# V3s register map
Vendor: Allwinner; Series: V3s; File version: 0.1
CPU: ARM Cortex-A7 MP1 0, little endian, MPU, no FPU, 0 interrupt priority bits
Registers are 32-bit, read-write, reset 0x0 unless marked. A register's access mark holds for its fields unless they carry their own. Offsets are from the block's base; [hi:lo] are bit positions; {n}, {i} and the like mark numbered series; 'fields as' and 'values as' point back to an identical list.

## CSI0
Base 0x01CB0000
Same registers: CSI1 0x01CB4000
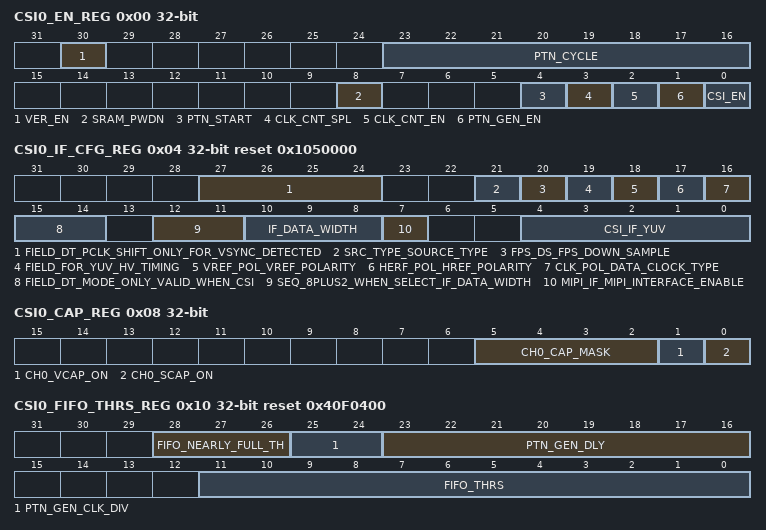
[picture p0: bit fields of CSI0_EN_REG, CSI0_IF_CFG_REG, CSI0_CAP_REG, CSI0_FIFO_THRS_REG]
0x00 CSI0_EN_REG
  [30] VER_EN — CSI Version Register Read Enable: 0: Disable 1: Enable
    0=Disable; 1=Enable
  [23:16] PTN_CYCLE — Pattern generating cycle counter. The pattern in dram will be generated in cycles of PTN_CYCLE+1.
  [8] SRAM_PWDN — 0: SRAM in normal 1: SRAM in power down
    0=SRAM_in_normal; 1=SRAM in power down
  [4] PTN_START — CSI Pattern Generating Start 0: Finish other: Start Software write this bit to 1 to start pattern generating from DRAM. When finished, the hardware will clear this bit to 0 automatically. Generating cycles depends on PTN_CYCLE.
    0=Finish other: Start Software write this bit to 1 to start pattern generating from DRAM. When finished, the hardware will clear this bit to 0 automatically. Generating cycles depends on PTN_CYCLE.
  [3] CLK_CNT_SPL — Sampling time for clk counter per frame 0: Sampling clock counter every frame done 1: Sampling clock counter every vsync
    0=Sampling clock counter every frame done; 1=Sampling_clock_counter_every_vsync
  [2] CLK_CNT_EN — clk count per frame enable
  [1] PTN_GEN_EN — Pattern Generation Enable
  [0] CSI_EN — Enable 0: Reset and disable the CSI module 1: Enable the CSI module
    0=Reset and disable the CSI module; 1=Enable the CSI module
0x04 CSI0_IF_CFG_REG reset 0x1050000 (reset mask 0xF3FD89F)
  [27:24] FIELD_DT_PCLK_SHIFT_ONLY_FOR_VSYNC_DETECTED — FIELD_DT_PCLK_SHIFT Only for vsync detected field mode,the odd field permitted pclk shift = 4* FIELD_DT_PCLK_SHIFT
  [21] SRC_TYPE_SOURCE_TYPE — SRC_TYPE Source type 0: Progressed 1: Interlaced
    0=Progressed; 1=Interlaced
  [20] FPS_DS_FPS_DOWN_SAMPLE — FPS_DS Fps down sample 0: no down sample 1: 1/2 fps, only receives the first frame every 2 frames
    0=no down sample; 1=_1_slash_2 (1/2 fps, only receives the first frame every 2 frames)
  [19] FIELD_FOR_YUV_HV_TIMING — FIELD For YUV HV timing, Field polarity 0: negative(field=0 indicate odd, field=1 indicate even ) 1: positive(field=1 indicate odd, field=0 indicate even ) For BT656 timing, Field sequence 0: Normal sequence (field 0 first) 1: Inverse sequence (field 1 first)
    0=negative_openingparen_field_equals_0 (negative(field=0 indicate odd, field=1 indicate even )); 1=positive_openingparen_field_equals_1 (positive(field=1 indicate odd, field=0 indicate even ) For BT656 timing, Field sequence); 0=Normal sequence (field 0 first); 1=Inverse sequence (field 1 first)
  [18] VREF_POL_VREF_POLARITY — VREF_POL Vref polarity 0: negative 1: positive This register is not apply to CCIR656 interface.
    0=negative; 1=positive This register is not apply to CCIR656 interface
  [17] HERF_POL_HREF_POLARITY — HERF_POL Href polarity 0: negative 1: positive This register is not apply to CCIR656 interface.
    values as VREF_POL_VREF_POLARITY
  [16] CLK_POL_DATA_CLOCK_TYPE — CLK_POL Data clock type 0: active in rising edge 1: active in falling edge
    0=active_in_rising_edge; 1=active_in_falling_edge
  [15:14] FIELD_DT_MODE_ONLY_VALID_WHEN_CSI — Field_DT_MODE only valid when CSI_IF is YUV and source type is interlaced 00:by both field and vsync 01:by field 10:by vsync 11:reserved
  [12:11] SEQ_8PLUS2_WHEN_SELECT_IF_DATA_WIDTH — SEQ_8PLUS2 When select IF_DATA_WIDTH to be 8+2bit, odd/even pixel byte at CSI-D[11:4] will be rearranged to D[11:2]+2`b0 at the actual csi data bus according to these sequences: 00: 6`bx+D[9:8], D[7:0] 01: D[9:2], 6`bx+D[1:0] 10: D[7:0], D[9:8]+6`bx 11: D[7:0], 6`bx+D[9:8]
    0=_6`bx_plus_D[9_colon_8]_comma__D[7_colon_0] (6`bx+D[9:8], D[7:0]); 1=D[9_colon_2]_comma__6`bx_plus_D[1_colon_0] (D[9:2], 6`bx+D[1:0]); 2=D[7_colon_0]_comma__D[9_colon_8]_plus_6`bx (D[7:0], D[9:8]+6`bx); 3=D[7_colon_0]_comma__6`bx_plus_D[9_colon_8] (D[7:0], 6`bx+D[9:8])
  [10:8] IF_DATA_WIDTH — 0 IF_DATA_WIDTH 000: 8 bit data bus 001: 10 bit data bus 010: 12 bit data bus 011: 8+2bit data bus 100:2x8bit data bus Other:reserved
    0=8 bit data bus; 1=10 bit data bus; 2=12 bit data bus; 3=_8_plus_2bit_data (8+2bit data bus); 4=2x8bit data bus Other:reserved
  [7] MIPI_IF_MIPI_INTERFACE_ENABLE — MIPI_IF MIPI Interface Enable: 0: CSI 1: MIPI
    0=CSI; 1=MIPI
  [4:0] CSI_IF_YUV — CSI_IF YUV: 00000: YUYV422 Interleaved or RAW (All data in one data bus) 00001: YUV422 UV Combined (16 bit interface with seperate syncs) CCIR656: 00100: YUYV422 Interleaved or RAW (All data in one data bus) 00101:YUV422 UV Combined (16 bit inrerface with embedded syncs,BT1120 ) Others: Reserved
0x08 CSI0_CAP_REG
  [5:2] CH0_CAP_MASK — Vsync number masked before capture.
  [1] CH0_VCAP_ON — Video capture control: Capture the video image data stream on channel 0. 0: Disable video capture If video capture is in progress, the CSI stops capturing image data at the end of the current frame, and all of the current frame data is wrote to output FIFO. 1: Enable video capture The CSI starts capturing image data at the start of the next frame.
    0=Disable video capture If video capture is in progress, the CSI stops capturing image data at the end of the current frame, and all of the current frame data is wrote to output FIFO; 1=Enable video capture The CSI starts capturing image data at the start of the next frame
  [0] CH0_SCAP_ON — Still capture control: Capture a single still image frame on channel 0. 0: Disable still capture. 1: Enable still capture The CSI module starts capturing image data at the start of the next frame. The CSI module captures only one frame of image data. This bit is self clearing and always reads as a 0.
    0=Disable still capture; 1=Enable still capture The CSI module starts capturing image data at the start of the next frame. The CSI module captures only one frame of image data. This bit is self clearing and always reads as a 0.
0x0C CSI0_SYNC_CNT_REG
  [23:0] SYNC_CNT ro — The counter value between vsync of CSI0 channel 0 and vsync of CSI1 channel 0 , using 24MHz.
0x10 CSI0_FIFO_THRS_REG reset 0x40F0400
  [28:26] FIFO_NEARLY_FULL_TH — The threshold of FIFO being nearly full. Indicates that the ISP should stop writing. Only valid when ISP is enabled. 0~7: The smaller the value, the flag of FIFO being nearly full is easier to reach.
  [25:24] PTN_GEN_CLK_DIV — Packet generator clock divider
  [23:16] PTN_GEN_DLY — Clocks delayed before pattern generating start.
  [11:0] FIFO_THRS — When CSI0 FIFO occupied memory exceed the threshold, dram frequency can not change.
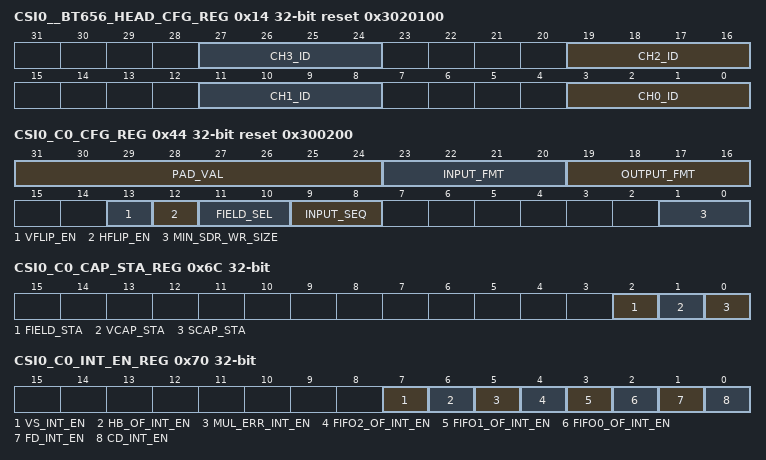
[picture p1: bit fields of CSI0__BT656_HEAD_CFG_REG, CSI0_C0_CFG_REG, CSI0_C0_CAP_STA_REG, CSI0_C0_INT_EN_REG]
0x14 CSI0__BT656_HEAD_CFG_REG reset 0x3020100
  [8n+3:8n] CH{n}_ID (n=0..3) — The low 4bit of BT656 header for channel {n} Only valid in BT656 multi-channel mode
0x30 CSI0_PTN_LEN_REG
  [31:0] PTN_LEN — The pattern length in byte when generating pattern.
0x34 CSI0_PTN_ADDR_REG
  [31:0] PTN_ADDR — The pattern DRAM address when generating pattern.
0x3C CSI0_VER_REG reset not defined
  [31:0] VER ro — Version of hardware circuit. Only can be read when version register read enable is on.
0x44 CSI0_C0_CFG_REG reset 0x300200
  [31:24] PAD_VAL — Padding value when OUTPUT_FMT is prgb888 0x00~0xff
  [23:20] INPUT_FMT — Input data format 0000: RAW stream 0001: reserved 0010: reserved 0011: YUV422 0100: YUV420 Others: reserved
    0=RAW (RAW stream); 3=YUV422; 4=YUV420 (YUV420 Others: reserved)
  [19:16] OUTPUT_FMT — Output data format When the input format is set RAW stream 0000: field-raw-8 0001: field-raw-10 0010: field-raw-12 0011: reserved 0100: field-rgb565 0101: field-rgb888 0110: field-prgb888 1000: frame-raw-8 1001: frame-raw-10 1010: frame-raw-12 1011: reserved 1100: frame-rgb565 1101: frame-rgb888 1110: frame-prgb888 When the input format is set YUV422 0000: field planar YCbCr 422 0001: field planar YCbCr 420 0010: frame planar YCbCr 420 0011: frame planar YCbCr 422 0100: field planar YCbCr 422 UV combined 0101: field planar YCbCr 420 UV combined 0110: frame planar YCbCr 420 UV combined 0111: frame planar YCbCr 422 UV combined 1000: field MB YCbCr 422 1001: field MB YCbCr 420 1010: frame MB YCbCr 420 1011: frame MB YCbCr 422 1100: field planar YCbCr 422 10bit UV combined 1101: field planar YCbCr 420 10bit UV combined 1110: Reserved 1111: Reserved When the input format is set YUV420 0000: Reserved 0001: field planar YCbCr 420 0010: frame planar YCbCr 420 0011: Reserved 0100: Reserved 0101: field planar YCbCr 420 UV combined 0110: frame planar YCbCr 420 UV combined 0111: Reserved 1000: Reserved 1001: field MB YCbCr 420 1010: frame MB YCbCr 420 1011: Reserved 1100: Reserved 1101: field planar YCbCr 420 10bit UV combined 1110: Reserved 1111: Reserved Others: reserved
  [13] VFLIP_EN — Vertical flip enable When enabled, the received data will be arranged in vertical flip. 0:Disable 1:Enable
  [12] HFLIP_EN — Horizontal flip enable When enabled, the received data will be arranged in horizontal flip. 0:Disable 1:Enable
  [11:10] FIELD_SEL — Field selection. 00: capturing with field 1. 01: capturing with field 2. 10: capturing with either field. 11: reserved
    0=capturing_with_field_1; 1=capturing_with_field_2; 2=capturing_with_either_field
  [9:8] INPUT_SEQ — Input data sequence, only valid for YUV422 and YUV420 input format. All data interleaved in one channel: 00: YUYV 01: YVYU 10: UYVY 11: VYUY Y and UV in separated channel: x0: UV x1: VU
    0=YUYV; 1=YVYU; 2=UYVY; 3=VYUY (VYUY Y and UV in separated channel:); 0=UV; 1=VU
  [1:0] MIN_SDR_WR_SIZE — Minimum size of SDRAM block write 0: 256 bytes (if hflip is enable, always select 256 bytes) 1: 512 bytes 2: 1k bytes 3: 2k bytes
    2=_1k (1k bytes); 3=_2k (2k bytes)
0x4C CSI0_C0_SCALE_REG
  [0] QUART_EN — When this bit is set to 1, input image will be decimated to quarter size. All input format are supported.
{0x50+8i} CSI0_C0_F{i}_BUFA_REG (i=0..2)
  [31:0] C0F{i}_BUFA — FIFO {i} output buffer-A address
0x6C CSI0_C0_CAP_STA_REG
  [2] FIELD_STA ro — The status of the received field 0: Field 0 1: Field 1
    0=Field_0; 1=Field_1
  [1] VCAP_STA ro — Video capture in progress Indicates the CSI is capturing video image data (multiple frames). The bit is set at the start of the first frame after enabling video capture. When software disables video capture, it clears itself after the last pixel of the current frame is captured.
  [0] SCAP_STA ro — Still capture in progress Indicates the CSI is capturing still image data (single frame). The bit is set at the start of the first frame after enabling still frame capture. It clears itself after the last pixel of the first frame is captured. For CCIR656 interface, if the output format is frame planar YCbCr 420 mode, the frame end means the field2 end, the other frame end means filed end.
0x70 CSI0_C0_INT_EN_REG
  [7] VS_INT_EN — vsync flag The bit is set when vsync come. And at this time load the buffer address for the coming frame. So after this irq come, change the buffer address could only effect next frame
  [6] HB_OF_INT_EN — Hblank FIFO overflow The bit is set when 3 FIFOs still overflow after the hblank.
  [5] MUL_ERR_INT_EN — Multi-channel writing error Indicates error has been detected for writing data to a wrong channel.
  [4] FIFO2_OF_INT_EN — FIFO 2 overflow The bit is set when the FIFO 2 become overflow.
  [3] FIFO1_OF_INT_EN — FIFO 1 overflow The bit is set when the FIFO 1 become overflow.
  [2] FIFO0_OF_INT_EN — FIFO 0 overflow The bit is set when the FIFO 0 become overflow.
  [1] FD_INT_EN — Frame done Indicates the CSI has finished capturing an image frame. Applies to video capture mode. The bit is set after each completed frame capturing data is writed to buffer as long as video capture remains enabled.
  [0] CD_INT_EN — Capture done Indicates the CSI has completed capturing the image data. For still capture, the bit is set when one frame data has been wrote to buffer. For video capture, the bit is set when the last frame has been wrote to buffer after video capture has been disabled. For CCIR656 interface, if the output format is frame planar YCbCr 420 mode, the frame end means the field2 end, the other frame end means field end.
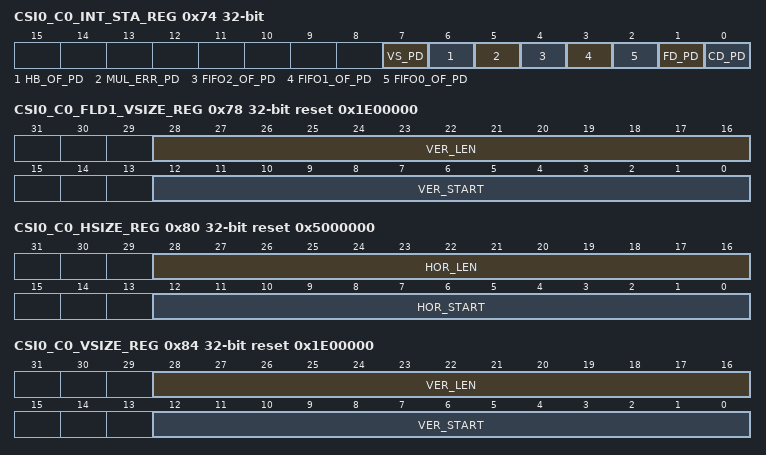
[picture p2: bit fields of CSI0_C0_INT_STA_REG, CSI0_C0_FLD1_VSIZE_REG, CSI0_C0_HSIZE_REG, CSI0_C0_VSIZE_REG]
0x74 CSI0_C0_INT_STA_REG
  [7] VS_PD — vsync flag
  [6] HB_OF_PD — Hblank FIFO overflow
  [5] MUL_ERR_PD — Multi-channel writing error
  [4] FIFO2_OF_PD — FIFO 2 overflow
  [3] FIFO1_OF_PD — FIFO 1 overflow
  [2] FIFO0_OF_PD — FIFO 0 overflow
  [1] FD_PD — Frame done
  [0] CD_PD — Capture done
0x78 CSI0_C0_FLD1_VSIZE_REG reset 0x1E00000
  [28:16] VER_LEN — Valid line number of filed1,only valid when CSI_IF is YUV and source type is interlaced.
  [12:0] VER_START — Vertical line start of filed1. data is valid from this line,only valid when CSI_IF is YUV and source type is interlaced.
0x80 CSI0_C0_HSIZE_REG reset 0x5000000
  [28:16] HOR_LEN — Horizontal pixel unit length. Valid pixel of a line.
  [12:0] HOR_START — Horizontal pixel unit start. Pixel is valid from this pixel.
0x84 CSI0_C0_VSIZE_REG reset 0x1E00000
  [28:16] VER_LEN — Vertical line length. Valid line number of a frame. Stand for line number of field0 when CSI_IF is YUV and source type is interlaced.
  [12:0] VER_START — Vertical line start. data is valid from this line. Stand for start line of field0 when CSI_IF is YUV and source type is interlaced.
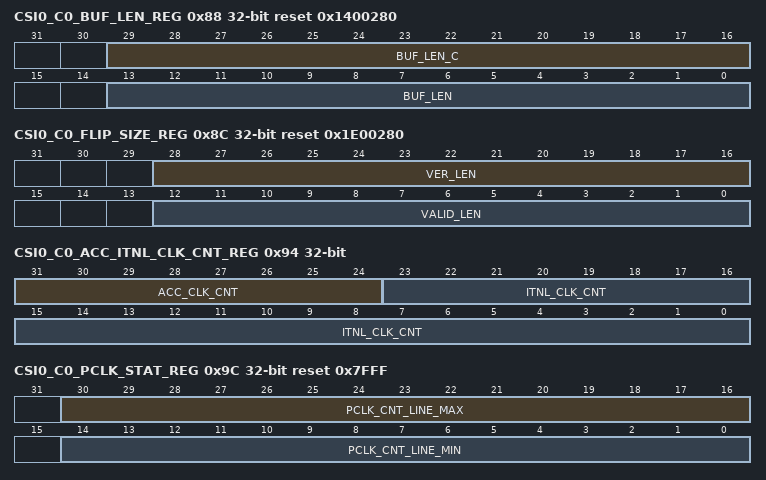
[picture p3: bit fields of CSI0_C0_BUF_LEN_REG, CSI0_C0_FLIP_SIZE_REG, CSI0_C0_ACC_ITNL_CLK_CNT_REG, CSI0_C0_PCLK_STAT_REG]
0x88 CSI0_C0_BUF_LEN_REG reset 0x1400280
  [29:16] BUF_LEN_C — Buffer length of chroma C in a line. Unit is byte.
  [13:0] BUF_LEN — Buffer length of luminance Y in a line. Unit is byte.
0x8C CSI0_C0_FLIP_SIZE_REG reset 0x1E00280
  [28:16] VER_LEN — Vertical line number when in vflip mode.
  [12:0] VALID_LEN — Valid components of a line when in flip mode.
0x90 CSI0_C0_FRM_CLK_CNT_REG
  [23:0] FRM_CLK_CNT ro — Counter value between every frame. For instant hardware frame rate statics. The internal counter is added by one every 24MHz clock cycle. When frame done or vsync comes, the internal counter value is sampled to FRM_CLK_CNT, and cleared to 0.
0x94 CSI0_C0_ACC_ITNL_CLK_CNT_REG
  [31:24] ACC_CLK_CNT ro — The accumulated value of FRM_CLK_CNT for software frame rate statics. Every interrupt of frame done, the software check this accumulated value and clear it to 0. If the ACC_CLK_CNT is larger than 1, the software has lost frame. When frame done or vsync comes, ACC_CLK_CNT = ACC_CLK_CNT + 1, and cleared to 0 when writing 0 to this register.
  [23:0] ITNL_CLK_CNT ro — The instant value of internal frame clock counter. When frame done interrupt comes, the software can query this counter for judging whether it is the time for updating the double buffer address registers.
0x98 CSI0_C0_FIFO_STAT_REG
  [11:0] FIFO_FRM_MAX ro — Indicates the maximum depth of FIFO being occupied for whole frame. Update at every vsync or framedone.
0x9C CSI0_C0_PCLK_STAT_REG reset 0x7FFF
  [30:16] PCLK_CNT_LINE_MAX ro — Indicates maximum pixel clock counter value for each line. Update at every vsync or framedone.
  [14:0] PCLK_CNT_LINE_MIN ro — Indicates minimum pixel clock counter value for each line. Update at every vsync or framedone.
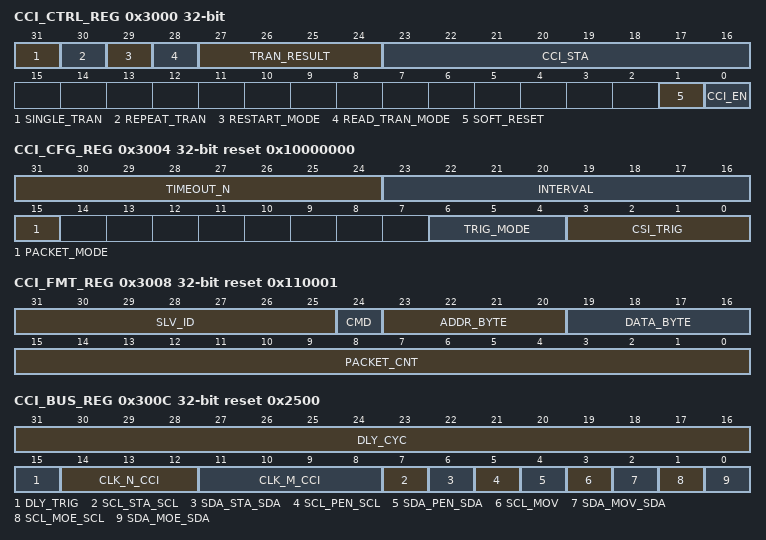
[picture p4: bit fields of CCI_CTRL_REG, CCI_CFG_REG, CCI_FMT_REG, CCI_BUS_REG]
0x3000 CCI_CTRL_REG (reset mask 0xFF000003)
  [31] SINGLE_TRAN — 0: Transmission idle 1: Start single transmission Automatically cleared to `0` when finished. Abort current transmission immediately if changing from `1` to `0`. If slave not respond for the expected status over the time defined by TIMEOUT, current transmission will stop. PACKET_CNT will return the sequence number when transmission fail. All format setting and data will be loaded from registers and FIFO when transmission start.
    0=Transmission_idle; 1=Start single transmission Automatically cleared to `0` when finished. Abort current transmission immediately if changing from `1` to `0`. If slave not respond for the expected status over the time defined by TIMEOUT, current transmission will stop. PACKET_CNT will return the sequence number when transmission fail. All format setting and data will be loaded from registers and FIFO when transmission start.
  [30] REPEAT_TRAN — 0: transmission idle 1: repeated transmission When this bit is set to 1, transmission repeats when trigger signal (such as VSYNC/ VCAP done ) repeats. If changing this bit from `1` to `0` during transmission, the current transmission will be guaranteed then stop.
    0=transmission_idle; 1=repeated transmission When this bit is set to 1, transmission repeats when trigger signal (such as VSYNC/ VCAP done ) repeats. If changing this bit from `1` to `0` during transmission, the current transmission will be guaranteed then stop.
  [29] RESTART_MODE — 0: RESTART 1: STOP+START Define the CCI action after sending register address.
    0=RESTART; 1=STOP_plus_START (STOP+START Define the CCI action after sending register address.)
  [28] READ_TRAN_MODE — 0: send slave_id+W 1: do not send slave_id+W Setting this bit to 1 if reading from a slave which register width is equal to 0.
    0=send slave_id+W; 1=do not send slave_id+W Setting this bit to 1 if reading from a slave which register width is equal to 0
  [27:24] TRAN_RESULT ro — 000: OK 001: FAIL Other: Reserved
  [23:16] CCI_STA ro — 0x00: bus error 0x08: START condition transmitted 0x10: Repeated START condition transmitted 0x18: Address + Write bit transmitted, ACK received 0x20: Address + Write bit transmitted, ACK not received 0x28: Data byte transmitted in master mode, ACK received 0x30: Data byte transmitted in master mode, ACK not received 0x38: Arbitration lost in address or data byte 0x40: Address + Read bit transmitted, ACK received 0x48: Address + Read bit transmitted, ACK not received 0x50: Data byte received in master mode, ACK received 0x58: Data byte received in master mode, ACK not received 0x01: Timeout when sending 9th SCL clk Other: Reserved
  [1] SOFT_RESET — 0: normal 1: reset
    0=normal; 1=reset
  [0] CCI_EN — 0: Module disable 1: Module enable
    0=Module_disable; 1=Module_enable
0x3004 CCI_CFG_REG reset 0x10000000
  [31:24] TIMEOUT_N — When sending the 9th clock, assert fail signal when slave device did not response after N*FSCL cycles. And software must do a reset to CCI module and send a stop condition to slave.
  [23:16] INTERVAL — Define the interval between each packet in 40*FSCL cycles. 0~255
  [15] PACKET_MODE — Select where to load slave id / data width 0: Compact mode 1: Complete mode In compact mode, slave id/register width / data width will be loaded from CCI_FMT register, only address and data read from memory. In complete mode, they will be loaded from packet memory.
    0=Compact_mode; 1=Complete mode In compact mode, slave id/register width / data width will be loaded from CCI_FMT register, only address and data read from memory. In complete mode, they will be loaded from packet memory.
  [6:4] TRIG_MODE — Transmit mode: 000: Immediately, no trigger 001: Reserved 010: CSI0 int trigger 011: CSI1 int trigger
    0=Immediately, no trigger; 2=CSI0 (CSI0 int trigger); 3=CSI1 (CSI1 int trigger)
  [3:0] CSI_TRIG — CSI Int trig signal select: 0000: First HREF start 0001: Last HREF done 0010: Line counter trigger other: Reserved
    0=First HREF start; 1=Last HREF done; 2=Line counter trigger other: Reserved
0x3008 CCI_FMT_REG reset 0x110001
  [31:25] SLV_ID — 7bit address
  [24] CMD — 0: write 1: read
    0=write; 1=read
  [23:20] ADDR_BYTE — How many bytes be sent as address 0~15
  [19:16] DATA_BYTE — How many bytes be sent/received as data 1~15 Normally use ADDR_DATA with 0_2, 1_1, 1_2, 2_1, 2_2 access mode. If DATA bytes is 0, transmission will not start. In complete mode, the ADDR_BYTE and DATA_BYTE is defined in a byte`s high/low 4bit.
  [15:0] PACKET_CNT — FIFO data be transmitted as PACKET_CNT packets in current format. Total bytes not exceed 32bytes.
0x300C CCI_BUS_REG reset 0x2500 (reset mask 0xFFFFFF37)
  [31:16] DLY_CYC — DLY_CYC 0~65535 FSCL cycles between each transmission
  [15] DLY_TRIG — DLY_TRIG 0: disable 1: execute transmission after internal counter delay when triggered
    0=disable; 1=execute transmission after internal counter delay when triggered
  [14:12] CLK_N_CCI — CLK_N CCI bus sampling clock F0=24MHz/2^CLK_N
  [11:8] CLK_M_CCI — CLK_M CCI output SCL frequency is FSCL=F1/10=(F0/(CLK_M+1))/10
  [7] SCL_STA_SCL ro — SCL_STA SCL current status
  [6] SDA_STA_SDA ro — SDA_STA SDA current status
  [5] SCL_PEN_SCL — SCL_PEN SCL PAD enable
  [4] SDA_PEN_SDA — SDA_PEN SDA PAD enable
  [3] SCL_MOV — 0 SCL_MOV SCL manual output value
  [2] SDA_MOV_SDA — SDA_MOV SDA manual output value
  [1] SCL_MOE_SCL — SCL_MOE SCL manual output en
  [0] SDA_MOE_SDA — SDA_MOE SDA manual output en
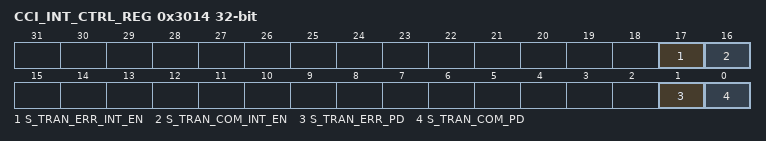
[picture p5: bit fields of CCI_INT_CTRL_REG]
0x3014 CCI_INT_CTRL_REG
  [17] S_TRAN_ERR_INT_EN, [16] S_TRAN_COM_INT_EN, [1] S_TRAN_ERR_PD, [0] S_TRAN_COM_PD
0x3018 CCI_LC_REG
  [12:0] LN_CNT — 0~8191: line counter send trigger when 1st~8192th line is received.
{0x3100+4i} CCI_FIFO_ACC_REG[{i}] (i=0..15) — CCI_FIFO_ACC_REG[{i}]
  [31:0] DATA_FIFO — From 0x100 to 0x13f, CCI data fifo is 64bytes, used in fifo input mode. CCI transmission read/write data from/to fifo in byte.
